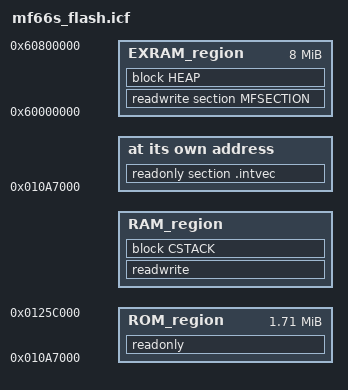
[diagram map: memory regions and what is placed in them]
/*###ICF### Section handled by ICF editor, don't touch! ****/
/*-Editor annotation file-*/
/* IcfEditorFile="$TOOLKIT_DIR$\config\ide\IcfEditor\cortex_v1_0.xml" */
/*-Specials-*/
define symbol __ICFEDIT_intvec_start__ = 0x01001000 + (76 + 12 + 512 + 64) * 1024;
/*-Memory Regions-*/
define symbol __ICFEDIT_region_ROM_start__ = __ICFEDIT_intvec_start__;
define symbol __ICFEDIT_region_ROM_end__   = __ICFEDIT_intvec_start__ + 1748 * 1024;
define symbol __ICFEDIT_region_RAM_start__ = 0x20000000 + (64 * 1024);
define symbol __ICFEDIT_region_RAM_end__   = __ICFEDIT_region_RAM_start__ + (1024 - 64) * 1024;

define symbol __ICFEDIT_region_EXTRAM_start__ = 0x60000000;
define symbol __ICFEDIT_region_EXTRAM_end__   = 0x60800000;
/*-Sizes-*/
define symbol __ICFEDIT_size_cstack__ = 0x4000;
define symbol __ICFEDIT_size_heap__   = 0x700000;
/**** End of ICF editor section. ###ICF###*/



define memory mem with size = 4G;
define region ROM_region   = mem:[from __ICFEDIT_region_ROM_start__   to __ICFEDIT_region_ROM_end__];
define region RAM_region   = mem:[from __ICFEDIT_region_RAM_start__   to __ICFEDIT_region_RAM_end__];
define region EXRAM_region   = mem:[from __ICFEDIT_region_EXTRAM_start__ to __ICFEDIT_region_EXTRAM_end__];

define block CSTACK    with alignment = 8, size = __ICFEDIT_size_cstack__   { };
define block HEAP      with alignment = 8, size = __ICFEDIT_size_heap__     { };

initialize by copy { readwrite };
do not initialize  { section .noinit };

place at address mem:__ICFEDIT_intvec_start__ { readonly section .intvec };

place in ROM_region   { readonly };
place in RAM_region   { readwrite, block CSTACK};
                        
place in EXRAM_region { readwrite section MFSECTION, block HEAP };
